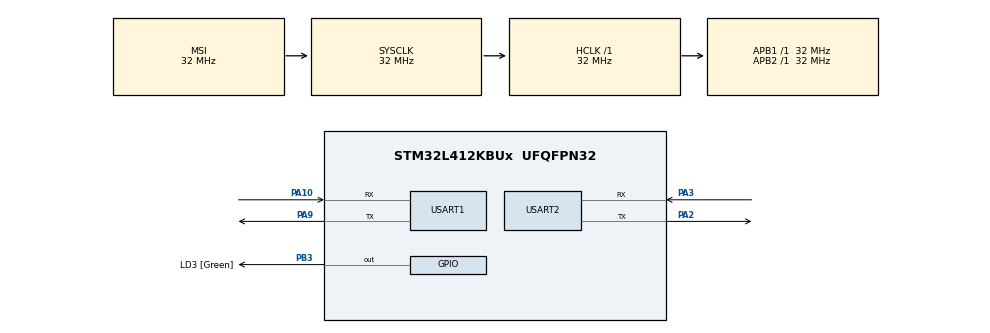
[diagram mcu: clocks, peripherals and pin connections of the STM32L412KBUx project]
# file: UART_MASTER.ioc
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Mcu.Family=STM32L4
Mcu.Name=STM32L412KBUx
Mcu.Package=UFQFPN32
NVIC.PriorityGroup=NVIC_PRIORITYGROUP_4
NVIC.USART1_IRQn=true\:0\:0\:false\:false\:true\:true\:true\:true
NVIC.USART2_IRQn=true\:0\:0\:false\:false\:true\:true\:true\:true
PA0-CK_IN.Mode=HSE-External-Clock-Source-for-LittleOrca
PA0-CK_IN.Signal=RCC_CK_IN
PA10.Mode=Asynchronous
PA10.Signal=USART1_RX
PA13\ (JTMS/SWDIO).GPIO_Label=SWDIO
PA13\ (JTMS/SWDIO).Mode=Serial_Wire
PA13\ (JTMS/SWDIO).Signal=SYS_JTMS-SWDIO
PA14\ (JTCK/SWCLK).GPIO_Label=SWCLK
PA14\ (JTCK/SWCLK).Mode=Serial_Wire
PA14\ (JTCK/SWCLK).Signal=SYS_JTCK-SWCLK
PA2.Mode=Asynchronous
PA2.Signal=USART2_TX
PA3.Mode=Asynchronous
PA3.Signal=USART2_RX
PA9.Mode=Asynchronous
PA9.Signal=USART1_TX
PB3\ (JTDO/TRACESWO).GPIO_Label=LD3 [Green]
PB3\ (JTDO/TRACESWO).Signal=GPIO_Output
PC14-OSC32_IN\ (PC14).Mode=LSE-External-Oscillator
PC14-OSC32_IN\ (PC14).Signal=RCC_OSC32_IN
PC15-OSC32_OUT\ (PC15).Mode=LSE-External-Oscillator
PC15-OSC32_OUT\ (PC15).Signal=RCC_OSC32_OUT
ProjectManager.HeapSize=0x200
ProjectManager.StackSize=0x400
ProjectManager.TargetToolchain=STM32CubeIDE
RCC.ADCFreq_Value=32000000
RCC.AHBFreq_Value=32000000
RCC.APB1Freq_Value=32000000
RCC.APB1TimFreq_Value=32000000
RCC.APB2Freq_Value=32000000
RCC.APB2TimFreq_Value=32000000
RCC.CortexFreq_Value=32000000
RCC.FLatency=FLASH_LATENCY_1
RCC.HCLKFreq_Value=32000000
RCC.HSE_VALUE=8000000
RCC.HSI48_VALUE=48000000
RCC.HSICalibrationValue=64
RCC.HSI_VALUE=16000000
RCC.LSE_Drive_Capability=RCC_LSEDRIVE_LOW
RCC.MSIClockRange=RCC_MSIRANGE_10
RCC.MSI_VALUE=32000000
RCC.SYSCLKFreq_VALUE=32000000
RCC.USBFreq_Value=32000000
RCC.VCOOutputFreq_Value=256000000
USART1.VirtualMode-Asynchronous=VM_ASYNC
USART2.VirtualMode-Asynchronous=VM_ASYNC
board=NUCLEO-L412KB

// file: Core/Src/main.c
// Copyright 2026 Tobiasz_Kandziora
#include "main.h" // NOLINT

/* USER CODE BEGIN Includes */
#include "master_app.h" // NOLINT
/* USER CODE END Includes */

UART_HandleTypeDef huart1;
UART_HandleTypeDef huart2;
/* USER CODE BEGIN PV */
uint8_t rx_data_uart1;
/* USER CODE END PV */

void SystemClock_Config(void);
static void MX_GPIO_Init(void);
static void MX_USART1_UART_Init(void);
static void MX_USART2_UART_Init(void);

int main(void) {

  /* MCU Configuration--------------------------------------------------------*/
  HAL_Init();

  /* Configure the system clock */
  SystemClock_Config();

  /* Initialize all configured peripherals */
  MX_GPIO_Init();
  MX_USART1_UART_Init();
  MX_USART2_UART_Init();
  /* USER CODE BEGIN 2 */

  // Inicjalizacja środowiska aplikacyjnego Mastera (stany, SIL)
  MasterApp_Init();

  // Otwarcie nasłuchiwania na magistrali w trybie przerwań (1 bajt)
  HAL_UART_Receive_IT(&huart1, &rx_data_uart1, 1);
  /* USER CODE END 2 */

  /* Infinite loop */
  while (1) {

    // Główny silnik zarządzający Masterem, m.in generuje Ping (Heartbeat)
    MasterApp_Process();
    /* USER CODE BEGIN 3 */
  }
  /*USER CODE END 3 */
}

void SystemClock_Config(void) {
  RCC_OscInitTypeDef RCC_OscInitStruct = { 0 };
  RCC_ClkInitTypeDef RCC_ClkInitStruct = { 0 };

  /** Configure the main internal regulator output voltage
   */
  if (HAL_PWREx_ControlVoltageScaling(PWR_REGULATOR_VOLTAGE_SCALE1) != HAL_OK) {
    Error_Handler();
  }

  /** Configure LSE Drive Capability
   */
  HAL_PWR_EnableBkUpAccess();
  __HAL_RCC_LSEDRIVE_CONFIG(RCC_LSEDRIVE_LOW);

  /** Initializes the RCC Oscillators according to the specified parameters
   * in the RCC_OscInitTypeDef structure.
   */
  RCC_OscInitStruct.OscillatorType = RCC_OSCILLATORTYPE_LSE
      | RCC_OSCILLATORTYPE_MSI;
  RCC_OscInitStruct.LSEState = RCC_LSE_ON;
  RCC_OscInitStruct.MSIState = RCC_MSI_ON;
  RCC_OscInitStruct.MSICalibrationValue = 0;
  RCC_OscInitStruct.MSIClockRange = RCC_MSIRANGE_10;
  RCC_OscInitStruct.PLL.PLLState = RCC_PLL_NONE;
  if (HAL_RCC_OscConfig(&RCC_OscInitStruct) != HAL_OK) {
    Error_Handler();
  }

  /** Initializes the CPU, AHB and APB buses clocks
   */
  RCC_ClkInitStruct.ClockType = RCC_CLOCKTYPE_HCLK | RCC_CLOCKTYPE_SYSCLK
      | RCC_CLOCKTYPE_PCLK1 | RCC_CLOCKTYPE_PCLK2;
  RCC_ClkInitStruct.SYSCLKSource = RCC_SYSCLKSOURCE_MSI;
  RCC_ClkInitStruct.AHBCLKDivider = RCC_SYSCLK_DIV1;
  RCC_ClkInitStruct.APB1CLKDivider = RCC_HCLK_DIV1;
  RCC_ClkInitStruct.APB2CLKDivider = RCC_HCLK_DIV1;

  if (HAL_RCC_ClockConfig(&RCC_ClkInitStruct, FLASH_LATENCY_1) != HAL_OK) {
    Error_Handler();
  }

  /** Enable MSI Auto calibration
   */
  HAL_RCCEx_EnableMSIPLLMode();
}

static void MX_USART1_UART_Init(void) {

  huart1.Instance = USART1;
  huart1.Init.BaudRate = 115200;
  huart1.Init.WordLength = UART_WORDLENGTH_8B;
  huart1.Init.StopBits = UART_STOPBITS_1;
  huart1.Init.Parity = UART_PARITY_NONE;
  huart1.Init.Mode = UART_MODE_TX_RX;
  huart1.Init.HwFlowCtl = UART_HWCONTROL_NONE;
  huart1.Init.OverSampling = UART_OVERSAMPLING_16;
  huart1.Init.OneBitSampling = UART_ONE_BIT_SAMPLE_DISABLE;
  huart1.AdvancedInit.AdvFeatureInit = UART_ADVFEATURE_NO_INIT;
  if (HAL_UART_Init(&huart1) != HAL_OK) {
    Error_Handler();
  }
}

static void MX_USART2_UART_Init(void) {

  huart2.Instance = USART2;
  huart2.Init.BaudRate = 115200;
  huart2.Init.WordLength = UART_WORDLENGTH_8B;
  huart2.Init.StopBits = UART_STOPBITS_1;
  huart2.Init.Parity = UART_PARITY_NONE;
  huart2.Init.Mode = UART_MODE_TX_RX;
  huart2.Init.HwFlowCtl = UART_HWCONTROL_NONE;
  huart2.Init.OverSampling = UART_OVERSAMPLING_16;
  huart2.Init.OneBitSampling = UART_ONE_BIT_SAMPLE_DISABLE;
  huart2.AdvancedInit.AdvFeatureInit = UART_ADVFEATURE_NO_INIT;
  if (HAL_UART_Init(&huart2) != HAL_OK) {
    Error_Handler();
  }
}

static void MX_GPIO_Init(void) {
  GPIO_InitTypeDef GPIO_InitStruct = { 0 };

  /* GPIO Ports Clock Enable */
  __HAL_RCC_GPIOC_CLK_ENABLE();
  __HAL_RCC_GPIOA_CLK_ENABLE();
  __HAL_RCC_GPIOB_CLK_ENABLE();

  /*Configure GPIO pin Output Level */
  HAL_GPIO_WritePin(LD3_GPIO_Port, LD3_Pin, GPIO_PIN_RESET);

  /*Configure GPIO pin : LD3_Pin */
  GPIO_InitStruct.Pin = LD3_Pin;
  GPIO_InitStruct.Mode = GPIO_MODE_OUTPUT_PP;
  GPIO_InitStruct.Pull = GPIO_NOPULL;
  GPIO_InitStruct.Speed = GPIO_SPEED_FREQ_LOW;
  HAL_GPIO_Init(LD3_GPIO_Port, &GPIO_InitStruct);

}

/* USER CODE BEGIN 4 */

/**
 * @brief Sprzętowe przerwanie odbioru pełnego znaku z UART (Callback).
 * @param huart Wskaźnik na strukturę portu z którego nadeszły dane.
 * @details Funkcja wyłapuje znaki w tle i przekierowuje je do maszyny
 * parsującej, po czym natychmiast wznawia nasłuchiwanie.
 */
void HAL_UART_RxCpltCallback(UART_HandleTypeDef *huart) {
  if (huart->Instance == USART1) {
    /* Przekazujemy odebrany znak do parsera w master_app */
    MasterApp_UART1_RxCallback(rx_data_uart1);

    /* Wznawiamy nasłuchiwanie */
    HAL_UART_Receive_IT(&huart1, &rx_data_uart1, 1);
  }
}

/**
 * @brief Callback wywoływany w przypadku awarii fizycznej na linii (np. odpięcie kabla).
 * @details Przekazuje sygnał do aplikacji o konieczności wyczyszczenia zepsutych buforów
 * i po cichu resetuje stan peryferii.
 */
void HAL_UART_ErrorCallback(UART_HandleTypeDef *huart) {
  if (huart->Instance == USART1) {
    MasterApp_UART_ErrorCallback();
    HAL_UART_Receive_IT(&huart1, &rx_data_uart1, 1);
  }
}
/* USER CODE END 4 */

void Error_Handler(void) {
  __disable_irq();
  while (1) {
  }
}
